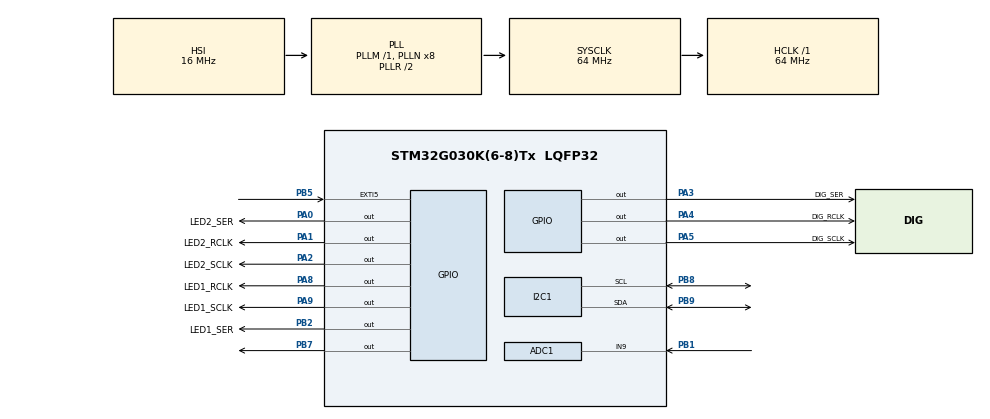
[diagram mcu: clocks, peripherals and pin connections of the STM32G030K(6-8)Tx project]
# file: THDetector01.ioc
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ADC1.Channel-0\#ChannelRegularConversion=ADC_CHANNEL_9
ADC1.NbrOfConversionFlag=1
ADC1.SamplingTimeCommon1=ADC_SAMPLETIME_160CYCLES_5
ADC1.SamplingTimeCommon2=ADC_SAMPLETIME_160CYCLES_5
ADC1.SelectedChannel=ADC_CHANNEL_9
ADC1.master=1
I2C1.Timing=0x10707DBC
Mcu.Family=STM32G0
Mcu.Name=STM32G030K(6-8)Tx
Mcu.Package=LQFP32
NVIC.EXTI4_15_IRQn=true\:1\:0\:true\:false\:true\:true\:true\:true
NVIC.TIM14_IRQn=true\:0\:0\:false\:false\:true\:true\:true\:true
PA0.GPIO_Label=LED2_SER
PA0.GPIO_ModeDefaultOutputPP=GPIO_MODE_OUTPUT_PP
PA0.GPIO_PuPd=GPIO_NOPULL
PA0.GPIO_Speed=GPIO_SPEED_FREQ_VERY_HIGH
PA0.PinState=GPIO_PIN_RESET
PA0.Signal=GPIO_Output
PA1.GPIO_Label=LED2_RCLK
PA1.GPIO_ModeDefaultOutputPP=GPIO_MODE_OUTPUT_PP
PA1.GPIO_PuPd=GPIO_NOPULL
PA1.GPIO_Speed=GPIO_SPEED_FREQ_VERY_HIGH
PA1.PinState=GPIO_PIN_RESET
PA1.Signal=GPIO_Output
PA13.Mode=Serial_Wire
PA13.Signal=SYS_SWDIO
PA14-BOOT0.Mode=Serial_Wire
PA14-BOOT0.Signal=SYS_SWCLK
PA2.GPIO_Label=LED2_SCLK
PA2.GPIO_ModeDefaultOutputPP=GPIO_MODE_OUTPUT_PP
PA2.GPIO_PuPd=GPIO_NOPULL
PA2.GPIO_Speed=GPIO_SPEED_FREQ_VERY_HIGH
PA2.PinState=GPIO_PIN_RESET
PA2.Signal=GPIO_Output
PA3.GPIO_Label=DIG_SER
PA3.GPIO_ModeDefaultOutputPP=GPIO_MODE_OUTPUT_PP
PA3.GPIO_PuPd=GPIO_NOPULL
PA3.GPIO_Speed=GPIO_SPEED_FREQ_VERY_HIGH
PA3.PinState=GPIO_PIN_RESET
PA3.Signal=GPIO_Output
PA4.GPIO_Label=DIG_RCLK
PA4.GPIO_ModeDefaultOutputPP=GPIO_MODE_OUTPUT_PP
PA4.GPIO_PuPd=GPIO_NOPULL
PA4.GPIO_Speed=GPIO_SPEED_FREQ_VERY_HIGH
PA4.PinState=GPIO_PIN_RESET
PA4.Signal=GPIO_Output
PA5.GPIO_Label=DIG_SCLK
PA5.GPIO_ModeDefaultOutputPP=GPIO_MODE_OUTPUT_PP
PA5.GPIO_PuPd=GPIO_NOPULL
PA5.GPIO_Speed=GPIO_SPEED_FREQ_VERY_HIGH
PA5.PinState=GPIO_PIN_RESET
PA5.Signal=GPIO_Output
PA8.GPIO_Label=LED1_RCLK
PA8.GPIO_ModeDefaultOutputPP=GPIO_MODE_OUTPUT_PP
PA8.GPIO_PuPd=GPIO_NOPULL
PA8.GPIO_Speed=GPIO_SPEED_FREQ_VERY_HIGH
PA8.PinState=GPIO_PIN_RESET
PA8.Signal=GPIO_Output
PA9.GPIO_Label=LED1_SCLK
PA9.GPIO_ModeDefaultOutputPP=GPIO_MODE_OUTPUT_PP
PA9.GPIO_PuPd=GPIO_NOPULL
PA9.GPIO_Speed=GPIO_SPEED_FREQ_VERY_HIGH
PA9.PinState=GPIO_PIN_RESET
PA9.Signal=GPIO_Output
PB1.Mode=IN9
PB1.Signal=ADC1_IN9
PB2.GPIO_Label=LED1_SER
PB2.Signal=GPIO_Output
PB5.GPIO_ModeDefaultEXTI=GPIO_MODE_IT_FALLING
PB5.GPIO_PuPd=GPIO_PULLUP
PB5.Signal=GPXTI5
PB7.PinState=GPIO_PIN_SET
PB7.Signal=GPIO_Output
PB8.Mode=I2C
PB8.Signal=I2C1_SCL
PB9.Mode=I2C
PB9.Signal=I2C1_SDA
ProjectManager.HeapSize=0x200
ProjectManager.StackSize=0x400
ProjectManager.TargetToolchain=MDK-ARM V5.32
RCC.ADCFreq_Value=64000000
RCC.AHBFreq_Value=64000000
RCC.CortexFreq_Value=64000000
RCC.EXTERNAL_CLOCK_VALUE=12288000
RCC.HCLKFreq_Value=64000000
RCC.HSE_VALUE=8000000
RCC.HSI_VALUE=16000000
RCC.LSE_VALUE=32768
RCC.SYSCLKFreq_VALUE=64000000
RCC.SYSCLKSource=RCC_SYSCLKSOURCE_PLLCLK
RCC.VCOOutputFreq_Value=128000000
TIM14.Period=10000-1
TIM14.Prescaler=6400-1
VP_TIM14_VS_ClockSourceINT.Mode=Enable_Timer
board=custom

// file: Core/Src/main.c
/* USER CODE BEGIN Header */
/**
  ******************************************************************************
  * @file           : main.c
  * @brief          : Main program body
  ******************************************************************************
  * @attention
  *
  * Copyright (c) 2024 STMicroelectronics.
  * All rights reserved.
  *
  * This software is licensed under terms that can be found in the LICENSE file
  * in the root directory of this software component.
  * If no LICENSE file comes with this software, it is provided AS-IS.
  *
  ******************************************************************************
  */
/* USER CODE END Header */
#include "main.h"
#include "adc.h"
#include "i2c.h"
#include "tim.h"
#include "gpio.h"

/* USER CODE BEGIN Includes */
#include "app.h"
/* USER CODE END Includes */

void SystemClock_Config(void);

int main(void)
{

  /* MCU Configuration--------------------------------------------------------*/

  /* Reset of all peripherals, Initializes the Flash interface and the Systick. */
  HAL_Init();

  /* Configure the system clock */
  SystemClock_Config();

  /* Initialize all configured peripherals */
  MX_GPIO_Init();
  MX_I2C1_Init();
  MX_ADC1_Init();
  MX_TIM14_Init();
  /* USER CODE BEGIN 2 */
	HAL_TIM_Base_Start_IT(&htim14);
  /* USER CODE END 2 */

  /* Infinite loop */
  while (1)
  {

    /* USER CODE BEGIN 3 */
		UnitTest();
  }
  /* USER CODE END 3 */
}

void SystemClock_Config(void)
{
  RCC_OscInitTypeDef RCC_OscInitStruct = {0};
  RCC_ClkInitTypeDef RCC_ClkInitStruct = {0};

  /** Configure the main internal regulator output voltage
  */
  HAL_PWREx_ControlVoltageScaling(PWR_REGULATOR_VOLTAGE_SCALE1);

  /** Initializes the RCC Oscillators according to the specified parameters
  * in the RCC_OscInitTypeDef structure.
  */
  RCC_OscInitStruct.OscillatorType = RCC_OSCILLATORTYPE_HSI;
  RCC_OscInitStruct.HSIState = RCC_HSI_ON;
  RCC_OscInitStruct.HSIDiv = RCC_HSI_DIV1;
  RCC_OscInitStruct.HSICalibrationValue = RCC_HSICALIBRATION_DEFAULT;
  RCC_OscInitStruct.PLL.PLLState = RCC_PLL_ON;
  RCC_OscInitStruct.PLL.PLLSource = RCC_PLLSOURCE_HSI;
  RCC_OscInitStruct.PLL.PLLM = RCC_PLLM_DIV1;
  RCC_OscInitStruct.PLL.PLLN = 8;
  RCC_OscInitStruct.PLL.PLLP = RCC_PLLP_DIV2;
  RCC_OscInitStruct.PLL.PLLR = RCC_PLLR_DIV2;
  if (HAL_RCC_OscConfig(&RCC_OscInitStruct) != HAL_OK)
  {
    Error_Handler();
  }

  /** Initializes the CPU, AHB and APB buses clocks
  */
  RCC_ClkInitStruct.ClockType = RCC_CLOCKTYPE_HCLK|RCC_CLOCKTYPE_SYSCLK
                              |RCC_CLOCKTYPE_PCLK1;
  RCC_ClkInitStruct.SYSCLKSource = RCC_SYSCLKSOURCE_PLLCLK;
  RCC_ClkInitStruct.AHBCLKDivider = RCC_SYSCLK_DIV1;
  RCC_ClkInitStruct.APB1CLKDivider = RCC_HCLK_DIV1;

  if (HAL_RCC_ClockConfig(&RCC_ClkInitStruct, FLASH_LATENCY_2) != HAL_OK)
  {
    Error_Handler();
  }
}

void Error_Handler(void)
{
  __disable_irq();
  while (1)
  {
  }
}
